VERSION "WUFR 24.1.0"

BS_: 1000000 : 0,0

BU_: FSB DAQ RSB CTRLB

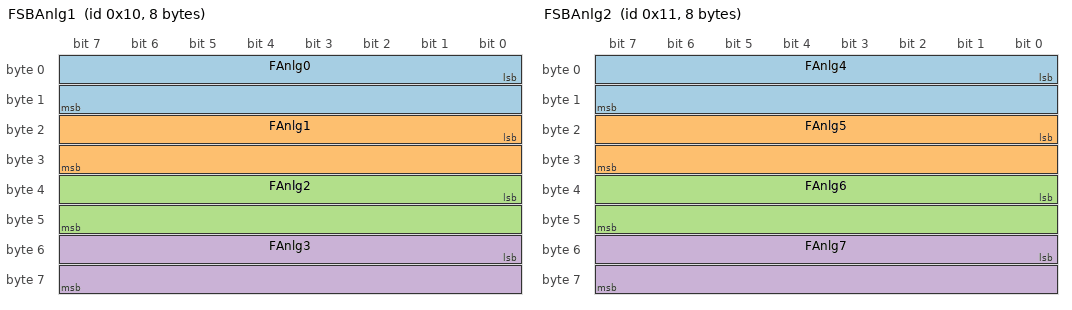
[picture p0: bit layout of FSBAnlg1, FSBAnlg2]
BO_ 16 FSBAnlg1: 8 FSB
 SG_ FAnlg0 : 0|16@1+ (0.001,0) [0|5] "V" DAQ
 SG_ FAnlg1 : 16|16@1+ (0.001,0) [0|5] "V" DAQ
 SG_ FAnlg2 : 32|16@1+ (0.001,0) [0|5] "V" DAQ
 SG_ FAnlg3 : 48|16@1+ (0.001,0) [0|5] "V" DAQ

BO_ 17 FSBAnlg2: 8 FSB
 SG_ FAnlg4 : 0|16@1+ (0.001,0) [0|5] "V" DAQ
 SG_ FAnlg5 : 16|16@1+ (0.001,0) [0|5] "V" DAQ
 SG_ FAnlg6 : 32|16@1+ (0.001,0) [0|5] "V" DAQ
 SG_ FAnlg7 : 48|16@1+ (0.001,0) [0|5] "V" DAQ

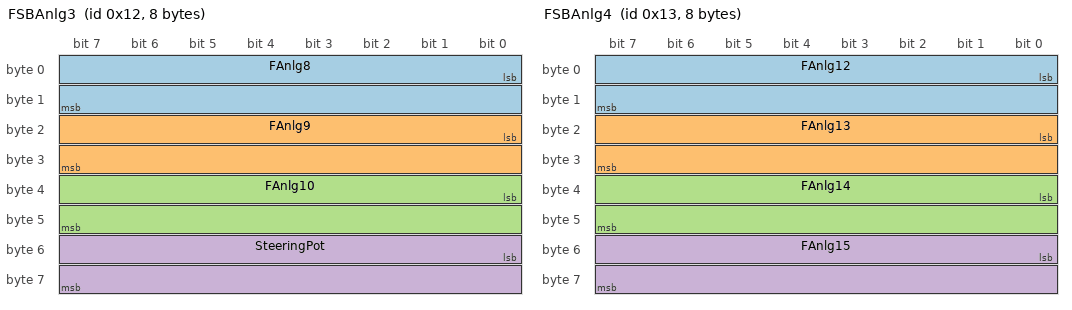
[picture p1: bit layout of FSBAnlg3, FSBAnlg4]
BO_ 18 FSBAnlg3: 8 FSB
 SG_ FAnlg8 : 0|16@1+ (0.001,0) [0|5] "V" DAQ
 SG_ FAnlg9 : 16|16@1+ (0.001,0) [0|5] "V" DAQ
 SG_ FAnlg10 : 32|16@1+ (0.001,0) [0|5] "V" DAQ
 SG_ SteeringPot : 48|16@1+ (0.7947,-302.975) [-90|90] "deg" DAQ

BO_ 19 FSBAnlg4: 8 FSB
 SG_ FAnlg12 : 0|16@1+ (0.001,0) [0|5] "V" DAQ
 SG_ FAnlg13 : 16|16@1+ (0.001,0) [0|5] "V" DAQ
 SG_ FAnlg14 : 32|16@1+ (0.001,0) [0|5] "V" DAQ
 SG_ FAnlg15 : 48|16@1+ (0.001,0) [0|5] "V" DAQ

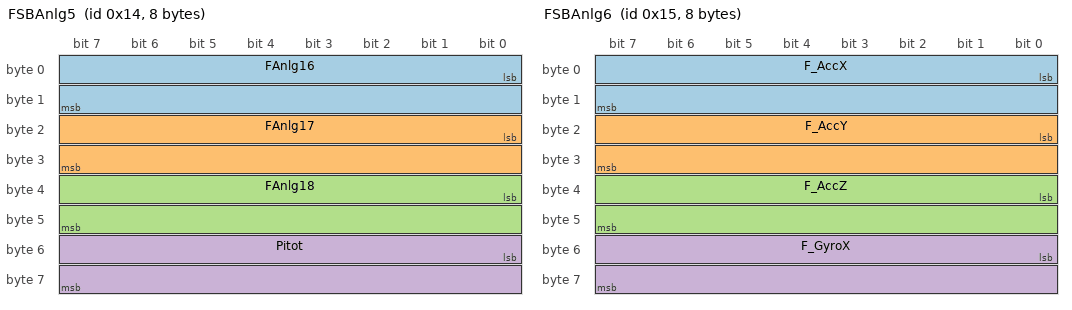
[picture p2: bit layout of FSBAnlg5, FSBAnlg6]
BO_ 20 FSBAnlg5: 8 FSB
 SG_ FAnlg16 : 0|16@1+ (0.001,0) [0|5] "V" DAQ
 SG_ FAnlg17 : 16|16@1+ (0.001,0) [0|5] "V" DAQ
 SG_ FAnlg18 : 32|16@1+ (0.001,0) [0|5] "V" DAQ
 SG_ Pitot : 48|16@1+ (0.0003151,-0.0166301) [0|0.18] "psi" DAQ

BO_ 21 FSBAnlg6: 8 FSB
 SG_ F_AccX : 0|16@1- (0.01,0) [-3276|3276] "m/s^2" DAQ
 SG_ F_AccY : 16|16@1- (0.01,0) [-3276|3276] "m/s^2" DAQ
 SG_ F_AccZ : 32|16@1- (0.01,0) [-3276|3276] "m/s^2" DAQ
 SG_ F_GyroX : 48|16@1- (0.01,0) [-3276|3276] "deg/s^2" DAQ

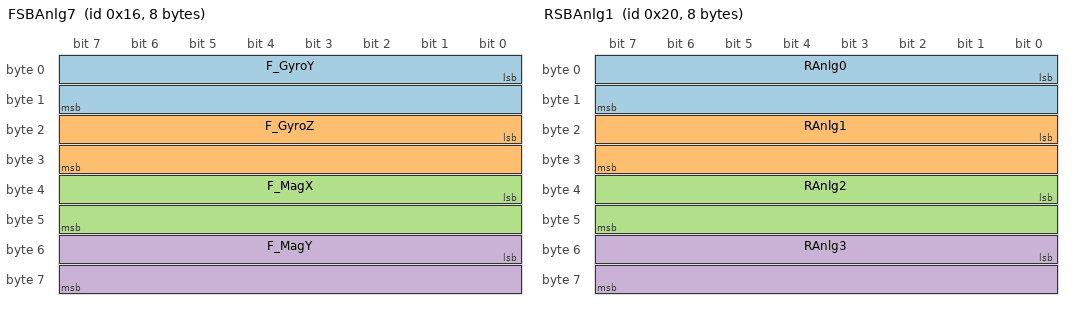
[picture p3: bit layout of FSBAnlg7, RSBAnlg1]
BO_ 22 FSBAnlg7: 8 FSB
 SG_ F_GyroY : 0|16@1- (0.01,0) [-3276|3276] "deg/s^2" DAQ
 SG_ F_GyroZ : 16|16@1- (0.01,0) [-3276|3276] "deg/s^2" DAQ
 SG_ F_MagX : 32|16@1- (0.01,0) [-3276|3276] "#" DAQ
 SG_ F_MagY : 48|16@1- (0.01,0) [-3276|3276] "#" DAQ

BO_ 23 FSBAnlg8: 8 FSB
 SG_ F_MagZ : 0|16@1+ (0.01,0) [-3276|3276] "#" DAQ

BO_ 32 RSBAnlg1: 8 RSB
 SG_ RAnlg0 : 0|16@1+ (0.001,0) [0|5] "V" DAQ
 SG_ RAnlg1 : 16|16@1+ (0.001,0) [0|5] "V" DAQ
 SG_ RAnlg2 : 32|16@1+ (0.001,0) [0|5] "V" DAQ
 SG_ RAnlg3 : 48|16@1+ (0.001,0) [0|5] "V" DAQ

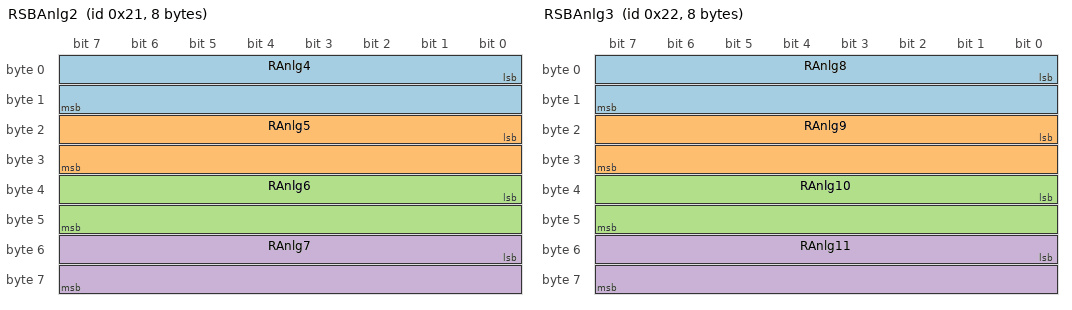
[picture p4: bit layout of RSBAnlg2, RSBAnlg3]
BO_ 33 RSBAnlg2: 8 RSB
 SG_ RAnlg4 : 0|16@1+ (0.001,0) [0|5] "V" DAQ
 SG_ RAnlg5 : 16|16@1+ (0.001,0) [0|5] "V" DAQ
 SG_ RAnlg6 : 32|16@1+ (0.001,0) [0|5] "V" DAQ
 SG_ RAnlg7 : 48|16@1+ (0.001,0) [0|5] "V" DAQ

BO_ 34 RSBAnlg3: 8 RSB
 SG_ RAnlg8 : 0|16@1+ (0.001,0) [0|5] "V" DAQ
 SG_ RAnlg9 : 16|16@1+ (0.001,0) [0|5] "V" DAQ
 SG_ RAnlg10 : 32|16@1+ (0.001,0) [0|5] "V" DAQ
 SG_ RAnlg11 : 48|16@1+ (0.001,0) [0|5] "V" DAQ

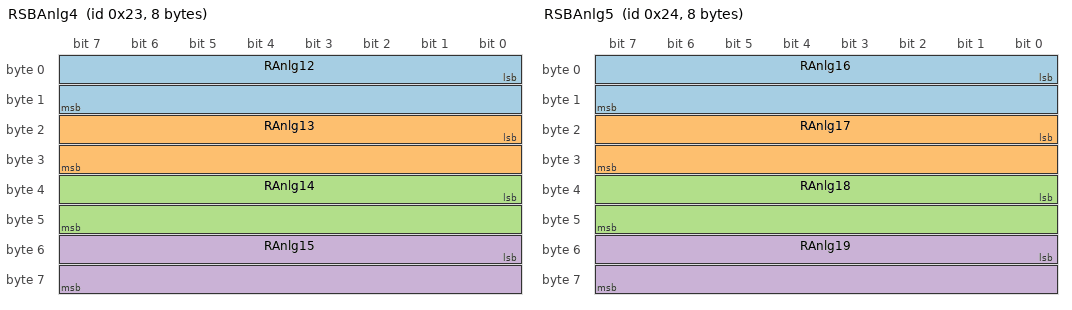
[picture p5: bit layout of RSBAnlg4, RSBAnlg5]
BO_ 35 RSBAnlg4: 8 RSB
 SG_ RAnlg12 : 0|16@1+ (0.001,0) [0|5] "V" DAQ
 SG_ RAnlg13 : 16|16@1+ (0.001,0) [0|5] "V" DAQ
 SG_ RAnlg14 : 32|16@1+ (0.001,0) [0|5] "V" DAQ
 SG_ RAnlg15 : 48|16@1+ (0.001,0) [0|5] "V" DAQ

BO_ 36 RSBAnlg5: 8 RSB
 SG_ RAnlg16 : 0|16@1+ (0.001,0) [0|5] "V" DAQ
 SG_ RAnlg17 : 16|16@1+ (0.001,0) [0|5] "V" DAQ
 SG_ RAnlg18 : 32|16@1+ (0.001,0) [0|5] "V" DAQ
 SG_ RAnlg19 : 48|16@1+ (0.001,0) [0|5] "V" DAQ

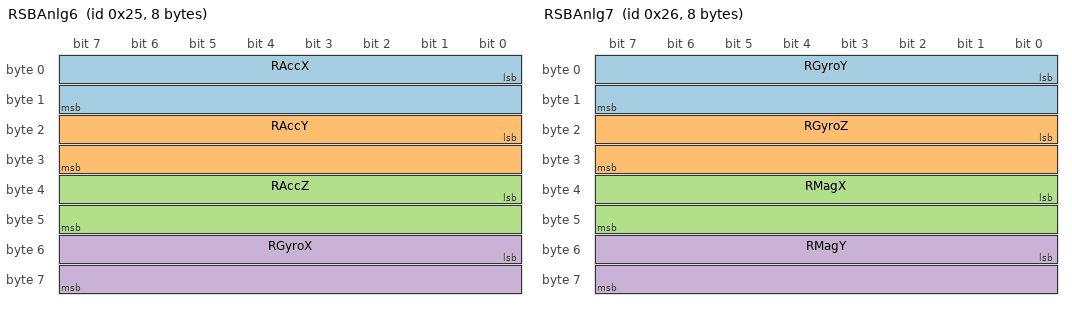
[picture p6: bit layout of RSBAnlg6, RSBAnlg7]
BO_ 37 RSBAnlg6: 8 RSB
 SG_ RAccX : 0|16@1- (0.01,0) [-3276|3276] "m/s^2" DAQ
 SG_ RAccY : 16|16@1- (0.01,0) [-3276|3276] "m/s^2" DAQ
 SG_ RAccZ : 32|16@1- (0.01,0) [-3276|3276] "m/s^2" DAQ
 SG_ RGyroX : 48|16@1- (0.01,0) [-3276|3276] "deg/s^2" DAQ

BO_ 38 RSBAnlg7: 8 RSB
 SG_ RGyroY : 0|16@1- (0.01,0) [-3276|3276] "deg/s^2" DAQ
 SG_ RGyroZ : 16|16@1- (0.01,0) [-3276|3276] "deg/s^2" DAQ
 SG_ RMagX : 32|16@1- (0.01,0) [-3276|3276] "#" DAQ
 SG_ RMagY : 48|16@1- (0.01,0) [-3276|3276] "#" DAQ

BO_ 39 RSBAnlg8: 8 RSB
 SG_ RMagZ : 0|16@1+ (0.01,0) [-3276|3276] "#" DAQ

BO_ 49 CTRLBrd: 1 CTRLB
 SG_ DRS : 0|1@1+ (1,0) [0|1] "Open:1/Close:0" DAQ
 SG_ ClutchPosition : 8|8@1+ (1,0) [0|360] "Deg" DAQ

CM_ BU_ FSB "Front sensor board";
CM_ BU_ RSB "Rear sensor board";
CM_ BU_ CTRLB "Control board";
BA_DEF_DEF_  "GenMsgCycleTime" 100;
